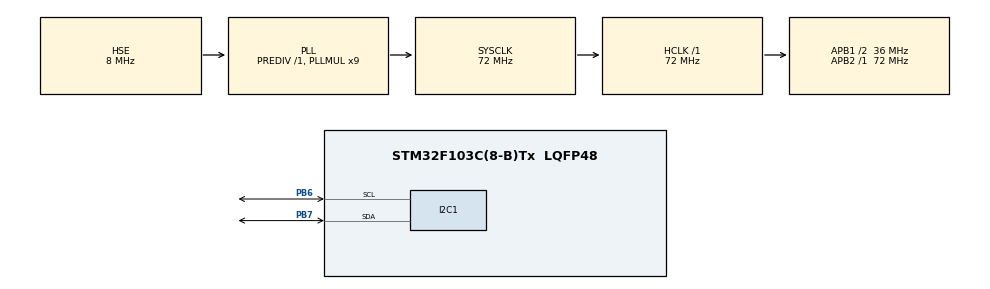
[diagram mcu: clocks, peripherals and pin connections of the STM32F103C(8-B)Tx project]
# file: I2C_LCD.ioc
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Mcu.Family=STM32F1
Mcu.Name=STM32F103C(8-B)Tx
Mcu.Package=LQFP48
NVIC.PriorityGroup=NVIC_PRIORITYGROUP_4
PA13.Mode=Serial_Wire
PA13.Signal=SYS_JTMS-SWDIO
PA14.Mode=Serial_Wire
PA14.Signal=SYS_JTCK-SWCLK
PB6.Mode=I2C
PB6.Signal=I2C1_SCL
PB7.Mode=I2C
PB7.Signal=I2C1_SDA
PD0-OSC_IN.Mode=HSE-External-Oscillator
PD0-OSC_IN.Signal=RCC_OSC_IN
PD1-OSC_OUT.Mode=HSE-External-Oscillator
PD1-OSC_OUT.Signal=RCC_OSC_OUT
ProjectManager.HeapSize=0x200
ProjectManager.StackSize=0x400
ProjectManager.TargetToolchain=MDK-ARM V5
RCC.AHBFreq_Value=72000000
RCC.APB1CLKDivider=RCC_HCLK_DIV2
RCC.APB1Freq_Value=36000000
RCC.APB1TimFreq_Value=72000000
RCC.APB2Freq_Value=72000000
RCC.APB2TimFreq_Value=72000000
RCC.HCLKFreq_Value=72000000
RCC.PLLMUL=RCC_PLL_MUL9
RCC.PLLSourceVirtual=RCC_PLLSOURCE_HSE
RCC.SYSCLKFreq_VALUE=72000000
RCC.SYSCLKSource=RCC_SYSCLKSOURCE_PLLCLK
RCC.USBFreq_Value=72000000
board=custom

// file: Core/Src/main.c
/* USER CODE BEGIN Header */
/**
  ******************************************************************************
  * @file           : main.c
  * @brief          : Main program body
  ******************************************************************************
  * @attention
  *
  * Copyright (c) 2023 STMicroelectronics.
  * All rights reserved.
  *
  * This software is licensed under terms that can be found in the LICENSE file
  * in the root directory of this software component.
  * If no LICENSE file comes with this software, it is provided AS-IS.
  *
  ******************************************************************************
  */
/* USER CODE END Header */
#include "main.h"
#include "string.h"
#include "stdio.h"
#define addr_pcf8574 0x4E

I2C_HandleTypeDef hi2c1;

void SystemClock_Config(void);
static void MX_GPIO_Init(void);
static void MX_I2C1_Init(void);
/* USER CODE BEGIN PFP */

void LCD_I2C_Write_CMD(uint8_t cmd)
{
	uint8_t buffer[4];
	buffer[0]=(cmd & 0xF0)|0x0C ;
	buffer[1]=(cmd & 0xF0)| 0x08;
	buffer[2]=(cmd <<4)&0xF0 |0x0C;
	buffer[3]=(cmd <<4)&0xF0 |0x08;
	HAL_I2C_Master_Transmit(&hi2c1,addr_pcf8574,(uint8_t *)buffer,4,HAL_MAX_DELAY);
}
void LCD_I2C_Write_Data(uint8_t data)
{
 uint8_t buffer[4]={(data & 0xF0) | 0x0D,(data & 0xF0) | 0x09,(data << 4)&0xF0 | 0x0D ,(data << 4)&0xF0 | 0x09 };
 HAL_I2C_Master_Transmit(&hi2c1,addr_pcf8574,buffer,4,HAL_MAX_DELAY);
}
void LCD_I2C_Clear()   // xoa man hinh
{
	LCD_I2C_Write_CMD(0x01);
	HAL_Delay(2);

}
void LCD_I2C_Location(uint8_t hang, uint8_t cot) //chon vi tri
{
 if(hang==0)
 {
	 LCD_I2C_Write_CMD(0x80+cot);
 }
 else if(hang==1)
	 {
	 LCD_I2C_Write_CMD(0xC0+cot);
	 }
}
void LCD_I2C_Init()
{

	LCD_I2C_Write_CMD(0x33); //lenh khoi tao
	LCD_I2C_Write_CMD(0x32); //khoi tao
	LCD_I2C_Write_CMD(0x28);  //che do 4 bit, 2 hang 5x7
	LCD_I2C_Write_CMD(0x0C);  //hien thi man hinh va tat con tro
	LCD_I2C_Write_CMD(0x06);  //tang con tro
	LCD_I2C_Write_CMD(0x01);  //xoa man hinh

	HAL_Delay(2);

	/*
	HAL_Delay(5);
	LCD_I2C_Write_CMD(0x30);
	HAL_Delay(5);
	LCD_I2C_Write_CMD(0x30);
	HAL_Delay(1);
	LCD_I2C_Write_CMD(0x30);
	HAL_Delay(10);
	LCD_I2C_Write_CMD(0x20);
	HAL_Delay(10);

	LCD_I2C_Write_CMD(0x28);
	HAL_Delay(1);
	LCD_I2C_Write_CMD(0x08);
	HAL_Delay(1);
	LCD_I2C_Write_CMD(0x01);
	HAL_Delay(1);
	LCD_I2C_Write_CMD(0x06);
	HAL_Delay(1);
	LCD_I2C_Write_CMD(0x0C);
	HAL_Delay(1);
	*/
}
void LCD_I2C_String(char *string){
for(int i=0;i<strlen(string);i++)
	{
LCD_I2C_Write_Data(string[i]);
  }
}
void LCD_I2C_Number(int number){
	char num2str[20];
	sprintf(num2str,"%d",number);
	for(int i=0;i<strlen(num2str);i++)
	{
LCD_I2C_Write_Data(num2str[i]);
  }
}

/*
#define SLAVE_ADDRESS_LCD 0x4E // change this according to ur setup

void lcd_send_cmd (char cmd)
{
  char data_u, data_l;
	uint8_t data_t[4];
	data_u = (cmd&0xf0);  // giu 4 bit cao 1111 0000=0xF0
	data_l = ((cmd<<4)&0xf0);
	data_t[0] = data_u|0x0C;  //en=1, rs=0 1100 rw=0 1-E-RW-RS
	data_t[1] = data_u|0x08;  //en=0, rs=0
	data_t[2] = data_l|0x0C;  //en=1, rs=0
	data_t[3] = data_l|0x08;  //en=0, rs=0
	HAL_I2C_Master_Transmit (&hi2c1, SLAVE_ADDRESS_LCD,(uint8_t *) data_t, 4, 100);
}

void lcd_send_data (char data)
{
	char data_u, data_l;
	uint8_t data_t[4];
	data_u = (data&0xf0);
	data_l = ((data<<4)&0xf0);
	data_t[0] = data_u|0x0D;  //en=1, rs=1  1101
	data_t[1] = data_u|0x09;  //en=0, rs=1  1001
	data_t[2] = data_l|0x0D;  //en=1, rs=1
	data_t[3] = data_l|0x09;  //en=0, rs=1
	HAL_I2C_Master_Transmit (&hi2c1, SLAVE_ADDRESS_LCD,(uint8_t *) data_t, 4, 100);
}

void lcd_clear (void)
{
	lcd_send_cmd (0x80);
	for (int i=0; i<70; i++)
	{
		lcd_send_data (' ');
	}
}

void lcd_put_cur(int row, int col)
{
    switch (row)
    {
        case 0:
            col |= 0x80;
            break;
        case 1:
            col |= 0xC0;
            break;
    }

    lcd_send_cmd (col);
}

void lcd_init (void)
{
	// 4 bit initialisation
	HAL_Delay(50);  // wait for >40ms
	lcd_send_cmd (0x30);
	HAL_Delay(5);  // wait for >4.1ms
	lcd_send_cmd (0x30);
	HAL_Delay(1);  // wait for >100us
	lcd_send_cmd (0x30);
	HAL_Delay(10);
	lcd_send_cmd (0x20);  // 4bit mode
	HAL_Delay(10);

  // dislay initialisation
	lcd_send_cmd (0x28); // Function set --> DL=0 (4 bit mode), N = 1 (2 line display) F = 0 (5x8 characters)
	HAL_Delay(1);
	lcd_send_cmd (0x08); //Display on/off control --> D=0,C=0, B=0  ---> display off
	HAL_Delay(1);
	lcd_send_cmd (0x01);  // clear display
	HAL_Delay(1);
	HAL_Delay(1);
	lcd_send_cmd (0x06); //Entry mode set --> I/D = 1 (increment cursor) & S = 0 (no shift)
	HAL_Delay(1);
	lcd_send_cmd (0x0C); //Display on/off control --> D = 1, C and B = 0. (Cursor and blink, last two bits)
}

void lcd_send_string (char *str)
{
	while (*str) lcd_send_data (*str++);
}
*/
/* USER CODE END PFP */

int main(void)
{

  /* MCU Configuration--------------------------------------------------------*/

  /* Reset of all peripherals, Initializes the Flash interface and the Systick. */
  HAL_Init();

  /* Configure the system clock */
  SystemClock_Config();

  /* Initialize all configured peripherals */
  MX_GPIO_Init();
  MX_I2C1_Init();
LCD_I2C_Init();

  /* Infinite loop */
  while (1)
  {
		HAL_Delay(500);
LCD_I2C_Location(0,0);
		LCD_I2C_String("Hello Iam from");
		HAL_Delay(1000);
		LCD_I2C_Location(1,3);
		LCD_I2C_Number(2023);
		HAL_Delay(1000);
		LCD_I2C_Clear();
		LCD_I2C_Location(0,3);
		LCD_I2C_String("Goodbye");
		HAL_Delay(1000);
		LCD_I2C_Clear();
		HAL_Delay(1000);

		/*
		lcd_put_cur(0,0);
		lcd_send_string("DIEN TU SONG PHU");
		HAL_Delay(2000);
		lcd_put_cur(1,2);
		lcd_send_string("CHAO CAC BAN!");
		HAL_Delay(7000);
                lcd_clear();

		*/

  }
}

void SystemClock_Config(void)
{
  RCC_OscInitTypeDef RCC_OscInitStruct = {0};
  RCC_ClkInitTypeDef RCC_ClkInitStruct = {0};

  /** Initializes the RCC Oscillators according to the specified parameters
  * in the RCC_OscInitTypeDef structure.
  */
  RCC_OscInitStruct.OscillatorType = RCC_OSCILLATORTYPE_HSE;
  RCC_OscInitStruct.HSEState = RCC_HSE_ON;
  RCC_OscInitStruct.HSEPredivValue = RCC_HSE_PREDIV_DIV1;
  RCC_OscInitStruct.HSIState = RCC_HSI_ON;
  RCC_OscInitStruct.PLL.PLLState = RCC_PLL_ON;
  RCC_OscInitStruct.PLL.PLLSource = RCC_PLLSOURCE_HSE;
  RCC_OscInitStruct.PLL.PLLMUL = RCC_PLL_MUL9;
  if (HAL_RCC_OscConfig(&RCC_OscInitStruct) != HAL_OK)
  {
    Error_Handler();
  }

  /** Initializes the CPU, AHB and APB buses clocks
  */
  RCC_ClkInitStruct.ClockType = RCC_CLOCKTYPE_HCLK|RCC_CLOCKTYPE_SYSCLK
                              |RCC_CLOCKTYPE_PCLK1|RCC_CLOCKTYPE_PCLK2;
  RCC_ClkInitStruct.SYSCLKSource = RCC_SYSCLKSOURCE_PLLCLK;
  RCC_ClkInitStruct.AHBCLKDivider = RCC_SYSCLK_DIV1;
  RCC_ClkInitStruct.APB1CLKDivider = RCC_HCLK_DIV2;
  RCC_ClkInitStruct.APB2CLKDivider = RCC_HCLK_DIV1;

  if (HAL_RCC_ClockConfig(&RCC_ClkInitStruct, FLASH_LATENCY_2) != HAL_OK)
  {
    Error_Handler();
  }
}

static void MX_I2C1_Init(void)
{

  hi2c1.Instance = I2C1;
  hi2c1.Init.ClockSpeed = 100000;
  hi2c1.Init.DutyCycle = I2C_DUTYCYCLE_2;
  hi2c1.Init.OwnAddress1 = 0;
  hi2c1.Init.AddressingMode = I2C_ADDRESSINGMODE_7BIT;
  hi2c1.Init.DualAddressMode = I2C_DUALADDRESS_DISABLE;
  hi2c1.Init.OwnAddress2 = 0;
  hi2c1.Init.GeneralCallMode = I2C_GENERALCALL_DISABLE;
  hi2c1.Init.NoStretchMode = I2C_NOSTRETCH_DISABLE;
  if (HAL_I2C_Init(&hi2c1) != HAL_OK)
  {
    Error_Handler();
  }

}

static void MX_GPIO_Init(void)
{

  /* GPIO Ports Clock Enable */
  __HAL_RCC_GPIOD_CLK_ENABLE();
  __HAL_RCC_GPIOA_CLK_ENABLE();
  __HAL_RCC_GPIOB_CLK_ENABLE();

}

void Error_Handler(void)
{
  __disable_irq();
  while (1)
  {
  }
}
